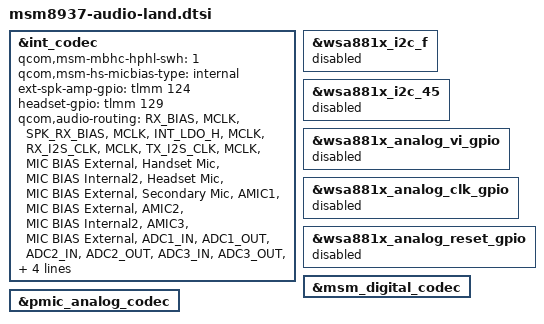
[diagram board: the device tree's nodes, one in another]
/*
 * Copyright (c) 2015-2017, The Linux Foundation. All rights reserved.
 *
 * This program is free software; you can redistribute it and/or modify
 * it under the terms of the GNU General Public License version 2 and
 * only version 2 as published by the Free Software Foundation.
 *
 * This program is distributed in the hope that it will be useful,
 * but WITHOUT ANY WARRANTY; without even the implied warranty of
 * MERCHANTABILITY or FITNESS FOR A PARTICULAR PURPOSE.  See the
 * GNU General Public License for more details.
 */

&int_codec {
	qcom,msm-mbhc-hphl-swh = <1>;
	qcom,msm-hs-micbias-type = "internal";
	ext-spk-amp-gpio = <&tlmm 124 0>;
	headset-gpio = <&tlmm 129 0>;
	qcom,audio-routing =
		"RX_BIAS", "MCLK",
		"SPK_RX_BIAS", "MCLK",
		"INT_LDO_H", "MCLK",
		"RX_I2S_CLK", "MCLK",
		"TX_I2S_CLK", "MCLK",
		"MIC BIAS External", "Handset Mic",
		"MIC BIAS Internal2", "Headset Mic",
		"MIC BIAS External", "Secondary Mic",
		"AMIC1", "MIC BIAS External",
		"AMIC2", "MIC BIAS Internal2",
		"AMIC3", "MIC BIAS External",
		"ADC1_IN", "ADC1_OUT",
		"ADC2_IN", "ADC2_OUT",
		"ADC3_IN", "ADC3_OUT",
		"PDM_IN_RX1", "PDM_OUT_RX1",
		"PDM_IN_RX2", "PDM_OUT_RX2",
		"PDM_IN_RX3", "PDM_OUT_RX3",
		"WSA_SPK OUT", "VDD_WSA_SWITCH",
		"SpkrMono WSA_IN", "WSA_SPK OUT";
		/delete-property/ asoc-wsa-codec-names;
		/delete-property/ asoc-wsa-codec-prefixes;
		/delete-property/ msm-vdd-wsa-switch-supply;
		/delete-property/ qcom,msm-vdd-wsa-switch-voltage;
		/delete-property/ qcom,msm-vdd-wsa-switch-current;
		/delete-property/ qcom,cdc-us-euro-gpios;
		/delete-property/ qcom,msm-gpios;
		/delete-property/ qcom,pinctrl-names;
		/delete-property/ pinctrl-names;
		/delete-property/ pinctrl-0;
		/delete-property/ pinctrl-1;
};

&wsa881x_i2c_f {
	status = "disabled";
};

&wsa881x_i2c_45 {
	status = "disabled";
};

&wsa881x_analog_vi_gpio {
	status = "disabled";
};

&wsa881x_analog_clk_gpio {
	status = "disabled";
};

&wsa881x_analog_reset_gpio {
	status = "disabled";
};
&msm_digital_codec {
	status = "okay";
};

&pmic_analog_codec {
	status = "okay";
};
